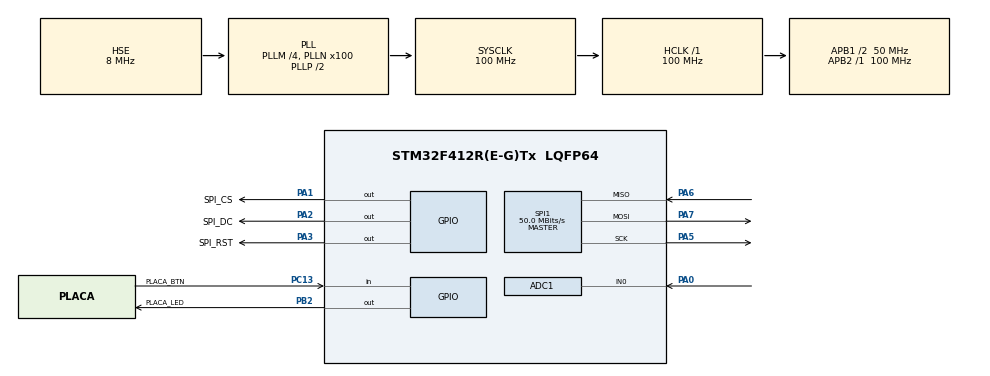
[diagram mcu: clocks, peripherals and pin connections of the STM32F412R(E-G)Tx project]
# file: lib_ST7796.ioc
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ADC1.Channel-0\#ChannelRegularConversion=ADC_CHANNEL_0
ADC1.ContinuousConvMode=ENABLE
ADC1.NbrOfConversionFlag=1
ADC1.Rank-0\#ChannelRegularConversion=1
ADC1.Resolution=ADC_RESOLUTION_10B
ADC1.SamplingTime-0\#ChannelRegularConversion=ADC_SAMPLETIME_3CYCLES
ADC1.master=1
Dma.Request0=SPI1_TX
Dma.SPI1_TX.0.Direction=DMA_MEMORY_TO_PERIPH
Dma.SPI1_TX.0.FIFOMode=DMA_FIFOMODE_DISABLE
Dma.SPI1_TX.0.Instance=DMA2_Stream2
Dma.SPI1_TX.0.MemDataAlignment=DMA_MDATAALIGN_HALFWORD
Dma.SPI1_TX.0.MemInc=DMA_MINC_ENABLE
Dma.SPI1_TX.0.Mode=DMA_NORMAL
Dma.SPI1_TX.0.PeriphDataAlignment=DMA_PDATAALIGN_HALFWORD
Dma.SPI1_TX.0.PeriphInc=DMA_PINC_DISABLE
Dma.SPI1_TX.0.Priority=DMA_PRIORITY_VERY_HIGH
Mcu.Family=STM32F4
Mcu.Name=STM32F412R(E-G)Tx
Mcu.Package=LQFP64
NVIC.DMA2_Stream2_IRQn=true\:0\:0\:false\:false\:true\:false\:true\:true
NVIC.PriorityGroup=NVIC_PRIORITYGROUP_4
PA0.Signal=ADCx_IN0
PA1.GPIO_Label=SPI_CS
PA1.GPIO_Speed=GPIO_SPEED_FREQ_VERY_HIGH
PA1.PinState=GPIO_PIN_SET
PA1.Signal=GPIO_Output
PA13.Mode=JTAG_4_pins
PA13.Signal=SYS_JTMS-SWDIO
PA14.Mode=JTAG_4_pins
PA14.Signal=SYS_JTCK-SWCLK
PA15.Mode=JTAG_4_pins
PA15.Signal=SYS_JTDI
PA2.GPIO_Label=SPI_DC
PA2.GPIO_Speed=GPIO_SPEED_FREQ_VERY_HIGH
PA2.PinState=GPIO_PIN_SET
PA2.Signal=GPIO_Output
PA3.GPIO_Label=SPI_RST
PA3.GPIO_Speed=GPIO_SPEED_FREQ_VERY_HIGH
PA3.PinState=GPIO_PIN_SET
PA3.Signal=GPIO_Output
PA5.Mode=Full_Duplex_Master
PA5.Signal=SPI1_SCK
PA6.Mode=Full_Duplex_Master
PA6.Signal=SPI1_MISO
PA7.Mode=Full_Duplex_Master
PA7.Signal=SPI1_MOSI
PB2.GPIO_Label=PLACA_LED
PB2.GPIO_ModeDefaultOutputPP=GPIO_MODE_OUTPUT_PP
PB2.GPIO_PuPd=GPIO_NOPULL
PB2.Signal=GPIO_Output
PB3.Mode=JTAG_4_pins
PB3.Signal=SYS_JTDO-SWO
PC10.Signal=SDIO_D2
PC11.Signal=SDIO_D3
PC12.Signal=SDIO_CK
PC13.GPIO_Label=PLACA_BTN
PC13.Signal=GPIO_Input
PC9.Signal=SDIO_D1
PD2.Signal=SDIO_CMD
PH0\ -\ OSC_IN.Mode=HSE-External-Oscillator
PH0\ -\ OSC_IN.Signal=RCC_OSC_IN
PH1\ -\ OSC_OUT.Mode=HSE-External-Oscillator
PH1\ -\ OSC_OUT.Signal=RCC_OSC_OUT
ProjectManager.HeapSize=0x200
ProjectManager.StackSize=0x400
ProjectManager.TargetToolchain=CMake
RCC.AHBFreq_Value=100000000
RCC.APB1CLKDivider=RCC_HCLK_DIV2
RCC.APB1Freq_Value=50000000
RCC.APB1TimFreq_Value=100000000
RCC.APB2Freq_Value=100000000
RCC.APB2TimFreq_Value=100000000
RCC.CortexFreq_Value=100000000
RCC.HCLKFreq_Value=100000000
RCC.HSE_VALUE=8000000
RCC.PLLM=4
RCC.PLLN=100
RCC.PLLQ=4
RCC.PLLSourceVirtual=RCC_PLLSOURCE_HSE
RCC.SYSCLKFreq_VALUE=100000000
RCC.SYSCLKSource=RCC_SYSCLKSOURCE_PLLCLK
RCC.USBFreq_Value=50000000
RCC.VCOOutputFreq_Value=200000000
SH.ADCx_IN0.0=ADC1_IN0,IN0
SPI1.BaudRatePrescaler=SPI_BAUDRATEPRESCALER_2
SPI1.CalculateBaudRate=50.0 MBits/s
SPI1.DataSize=SPI_DATASIZE_16BIT
SPI1.Direction=SPI_DIRECTION_2LINES
SPI1.Mode=SPI_MODE_MASTER
SPI1.VirtualType=VM_MASTER
board=custom

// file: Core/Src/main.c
/* USER CODE BEGIN Header */
/**
  ******************************************************************************
  * @file           : main.c
  * @brief          : Main program body
  ******************************************************************************
  * @attention
  *
  * Copyright (c) 2025 STMicroelectronics.
  * All rights reserved.
  *
  * This software is licensed under terms that can be found in the LICENSE file
  * in the root directory of this software component.
  * If no LICENSE file comes with this software, it is provided AS-IS.
  *
  ******************************************************************************
  */
/* USER CODE END Header */
#include "main.h"
#include "adc.h"
#include "dma.h"
#include "spi.h"
#include "gpio.h"

/* USER CODE BEGIN Includes */

#include "usr/main_st7796.h"

/* USER CODE END Includes */

void SystemClock_Config(void);

int main(void)
{

  /* MCU Configuration--------------------------------------------------------*/

  /* Reset of all peripherals, Initializes the Flash interface and the Systick. */
  HAL_Init();

  /* Configure the system clock */
  SystemClock_Config();

  /* Initialize all configured peripherals */
  MX_GPIO_Init();
  MX_DMA_Init();
  MX_SPI1_Init();
  MX_ADC1_Init();

  /* Infinite loop */
  while (1)
  {

    /* USER CODE BEGIN 3 */

	HAL_GPIO_TogglePin(PLACA_LED_GPIO_Port,PLACA_LED_Pin);
	HAL_Delay(250);
	HAL_GPIO_TogglePin(PLACA_LED_GPIO_Port,PLACA_LED_Pin);
	HAL_Delay(250);
	HAL_GPIO_TogglePin(PLACA_LED_GPIO_Port,PLACA_LED_Pin);
	HAL_Delay(250);
	HAL_GPIO_TogglePin(PLACA_LED_GPIO_Port,PLACA_LED_Pin);
	HAL_Delay(250);

	main_st7796();

  }
  /* USER CODE END 3 */
}

void SystemClock_Config(void)
{
  RCC_OscInitTypeDef RCC_OscInitStruct = {0};
  RCC_ClkInitTypeDef RCC_ClkInitStruct = {0};

  /** Configure the main internal regulator output voltage
  */
  __HAL_RCC_PWR_CLK_ENABLE();
  __HAL_PWR_VOLTAGESCALING_CONFIG(PWR_REGULATOR_VOLTAGE_SCALE1);

  /** Initializes the RCC Oscillators according to the specified parameters
  * in the RCC_OscInitTypeDef structure.
  */
  RCC_OscInitStruct.OscillatorType = RCC_OSCILLATORTYPE_HSE;
  RCC_OscInitStruct.HSEState = RCC_HSE_ON;
  RCC_OscInitStruct.PLL.PLLState = RCC_PLL_ON;
  RCC_OscInitStruct.PLL.PLLSource = RCC_PLLSOURCE_HSE;
  RCC_OscInitStruct.PLL.PLLM = 4;
  RCC_OscInitStruct.PLL.PLLN = 100;
  RCC_OscInitStruct.PLL.PLLP = RCC_PLLP_DIV2;
  RCC_OscInitStruct.PLL.PLLQ = 4;
  RCC_OscInitStruct.PLL.PLLR = 2;
  if (HAL_RCC_OscConfig(&RCC_OscInitStruct) != HAL_OK)
  {
    Error_Handler();
  }

  /** Initializes the CPU, AHB and APB buses clocks
  */
  RCC_ClkInitStruct.ClockType = RCC_CLOCKTYPE_HCLK|RCC_CLOCKTYPE_SYSCLK
                              |RCC_CLOCKTYPE_PCLK1|RCC_CLOCKTYPE_PCLK2;
  RCC_ClkInitStruct.SYSCLKSource = RCC_SYSCLKSOURCE_PLLCLK;
  RCC_ClkInitStruct.AHBCLKDivider = RCC_SYSCLK_DIV1;
  RCC_ClkInitStruct.APB1CLKDivider = RCC_HCLK_DIV2;
  RCC_ClkInitStruct.APB2CLKDivider = RCC_HCLK_DIV1;

  if (HAL_RCC_ClockConfig(&RCC_ClkInitStruct, FLASH_LATENCY_3) != HAL_OK)
  {
    Error_Handler();
  }
}

void Error_Handler(void)
{
  __disable_irq();
  while (1)
  {
  }
}
